# G32F031 register map
File version: 1.0
CPU: CM0PLUS r0p1, little endian, no MPU, no FPU, 2 interrupt priority bits
Registers are 32-bit, read-write, reset 0x0 unless marked. A register's access mark holds for its fields unless they carry their own. Offsets are from the block's base; [hi:lo] are bit positions; lines under a group give offsets from that group; {n}, {i} and the like mark numbered series.

## ADC — Analog-to-digital converter
Base 0x40005400
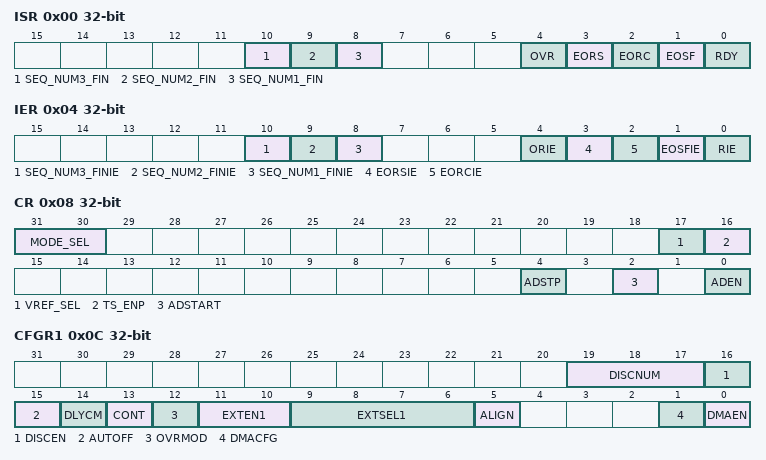
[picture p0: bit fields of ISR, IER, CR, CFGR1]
0x00 ISR — ADC interrupt and status register
  [10] SEQ_NUM3_FIN — NUM.3 of Sequential Section Sampling Finish
  [9] SEQ_NUM2_FIN — NUM.2 of Sequential Section Sampling Finish
  [8] SEQ_NUM1_FIN — NUM.1 of Sequential Section Sampling Finish
  [4] OVR — ADC group regular overrun flag
  [3] EORS — ADC group regular end of sequence conversions flag
  [2] EORC — ADC group regular end of unitary conversion flag
  [1] EOSF — ADC group regular end of sampling flag
  [0] RDY — ADC Ready Flag
0x04 IER — ADC interrupt enable register
  [10] SEQ_NUM3_FINIE — NUM.3 of Sequential Section Sampling Finish interrupt
  [9] SEQ_NUM2_FINIE — NUM.2 of Sequential Section Sampling Finish interrupt
  [8] SEQ_NUM1_FINIE — NUM.1 of Sequential Section Sampling Finish interrupt
  [4] ORIE — ADC group regular overrun interrupt
  [3] EORSIE — ADC group regular end of sequence conversions interrupt
  [2] EORCIE — ADC group regular end of unitary conversion interrupt
  [1] EOSFIE — ADC group regular end of sampling interrupt
  [0] RIE — ADC Ready Interrupt Enable
0x08 CR — ADC control register
  [31:30] MODE_SEL — ADC Work Mode Selection
  [17] VREF_SEL — ADC group injected conversion stop
  [16] TS_ENP — /
  [4] ADSTP — ADC group regular conversion stop
  [2] ADSTART — ADC group regular conversion start
  [0] ADEN — ADC enable
0x0C CFGR1 — ADC configuration register 1
  [19:17] DISCNUM — Discontinuous mode channel count
  [16] DISCEN — Discontinuous mode for regular channels
  [15] AUTOFF — Auto-Off Mode Enable
  [14] DLYCM — Delayed conversion mode
  [13] CONT — Single/continuous conversion mode for regular conversions
  [12] OVRMOD — Overrun Mode
  [11:10] EXTEN1 — ADC group regular external trigger polarity
  [9:6] EXTSEL1 — ADC group regular external trigger source
  [5] ALIGN — Data alignment
  [1] DMACFG — ADC DMA transfer configuration
  [0] DMAEN — ADC DMA transfer enable
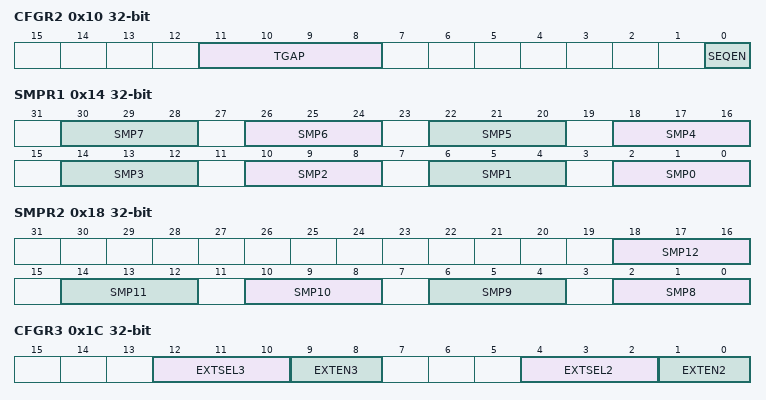
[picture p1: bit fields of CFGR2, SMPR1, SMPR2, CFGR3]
0x10 CFGR2 — ADC configuration register 2
  [11:8] TGAP — Time of The Gap between Conversions in Sequential Section Configure
  [0] SEQEN — Sequential Section Sampling Enable
0x14 SMPR1 — ADC sampling time register 1
  [4n+2:4n] SMP{n} (n=0..7) — ADC channel {n} sampling time selection
0x18 SMPR2 — ADC sampling time register 2
  [4n-30:4n-32] SMP{n} (n=8..12) — ADC channel {n} sampling time selection
0x1C CFGR3 — ADC configuration register 3
  [12:10] EXTSEL3 — External trigger selection for regular group
  [9:8] EXTEN3 — External trigger enable and polarity selection for regular channels
  [4:2] EXTSEL2 — External trigger selection for regular group
  [1:0] EXTEN2 — External trigger enable and polarity selection for regular channels
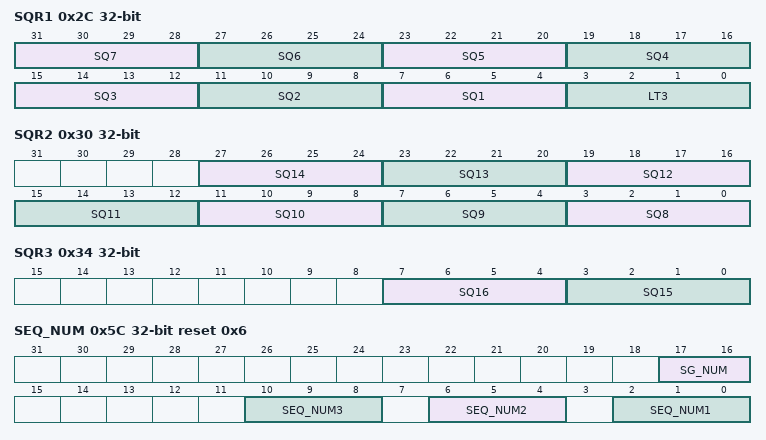
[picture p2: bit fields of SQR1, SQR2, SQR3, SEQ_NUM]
0x2C SQR1 — ADC group regular sequencer register 1
  [4n+3:4n] SQ{n} (n=1..7) — ADC group regular sequencer rank {n}
  [3:0] LT3 — ADC group regular sequencer scan length
0x30 SQR2 — ADC group regular sequencer register 2
  [4n-29:4n-32] SQ{n} (n=8..14) — ADC group regular sequencer rank {n}
0x34 SQR3 — ADC group regular sequencer register 3
  [7:4] SQ16 — ADC group regular sequencer rank 16
  [3:0] SQ15 — ADC group regular sequencer rank 15
0x38 DR ro — ADC group regular data register
  [15:0] RDATA — ADC group regular conversion data
{0x3C+4i} DATA{i} ro (i=0..2) — Segmented sampling result data {i}
  [15:0] RDATA{i} — Sequence Segmentation Sampling Result Data
0x48 DATA3 ro reset 0xC0 — Segmented sampling result data 3
  [15:0] RDATA3 — Sequence Segmentation Sampling Result Data
0x4C DATA4 ro reset 0x60 — Segmented sampling result data 4
  [15:0] RDATA4 — Sequence Segmentation Sampling Result Data
0x50 DATA5 ro reset 0x30 — Segmented sampling result data 5
  [15:0] RDATA5 — Sequence Segmentation Sampling Result Data
0x54 DATA6 ro reset 0x18 — Segmented sampling 6
  [15:0] RDATA6 — Sequence Segmentation Sampling Result Data
0x58 DATA7 ro reset 0xC — Segmented sampling result data 7
  [15:0] RDATA7 — Sequence Segmentation Sampling Result Data
0x5C SEQ_NUM reset 0x6 — The Number of Sequencial Section
  [17:16] SG_NUM — The Number of Sequencial Section
  [10:8] SEQ_NUM3 — Section3 Transmission Time Setup
  [6:4] SEQ_NUM2 — Section2 Transmission Time Setup
  [2:0] SEQ_NUM1 — Section1 Transmission Time Setup
